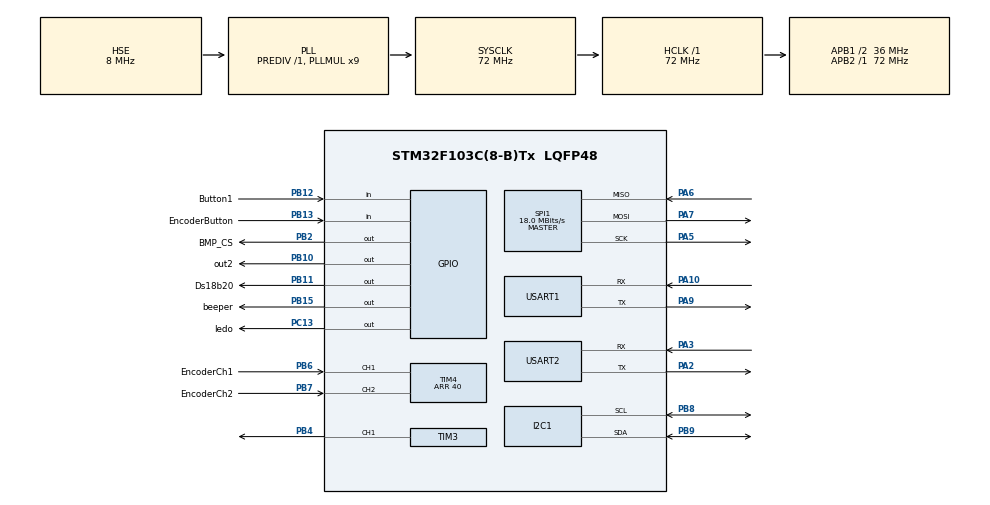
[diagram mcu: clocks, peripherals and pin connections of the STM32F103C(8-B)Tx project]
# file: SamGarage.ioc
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Dma.Request0=USART2_TX
Dma.USART2_TX.0.Direction=DMA_MEMORY_TO_PERIPH
Dma.USART2_TX.0.Instance=DMA1_Channel7
Dma.USART2_TX.0.MemDataAlignment=DMA_MDATAALIGN_BYTE
Dma.USART2_TX.0.MemInc=DMA_MINC_ENABLE
Dma.USART2_TX.0.Mode=DMA_NORMAL
Dma.USART2_TX.0.PeriphDataAlignment=DMA_PDATAALIGN_BYTE
Dma.USART2_TX.0.PeriphInc=DMA_PINC_DISABLE
Dma.USART2_TX.0.Priority=DMA_PRIORITY_LOW
I2C1.I2C_Mode=I2C_Fast
Mcu.Family=STM32F1
Mcu.Name=STM32F103C(8-B)Tx
Mcu.Package=LQFP48
NVIC.DMA1_Channel7_IRQn=true\:0\:0\:false\:false\:true\:false\:true\:true
NVIC.PriorityGroup=NVIC_PRIORITYGROUP_4
NVIC.RTC_IRQn=true\:0\:0\:false\:false\:true\:true\:true\:true
NVIC.TIM4_IRQn=true\:0\:0\:false\:false\:true\:true\:true\:true
NVIC.USART1_IRQn=true\:0\:0\:false\:false\:true\:true\:true\:true
NVIC.USART2_IRQn=true\:0\:0\:false\:false\:true\:true\:true\:true
PA10.Mode=Asynchronous
PA10.Signal=USART1_RX
PA13.Mode=Serial_Wire
PA13.Signal=SYS_JTMS-SWDIO
PA14.Mode=Serial_Wire
PA14.Signal=SYS_JTCK-SWCLK
PA2.Mode=Asynchronous
PA2.Signal=USART2_TX
PA3.Mode=Asynchronous
PA3.Signal=USART2_RX
PA5.Mode=Full_Duplex_Master
PA5.Signal=SPI1_SCK
PA6.Mode=Full_Duplex_Master
PA6.Signal=SPI1_MISO
PA7.Mode=Full_Duplex_Master
PA7.Signal=SPI1_MOSI
PA9.Mode=Asynchronous
PA9.Signal=USART1_TX
PB10.GPIO_Label=out2
PB10.GPIO_Speed=GPIO_SPEED_FREQ_HIGH
PB10.Signal=GPIO_Output
PB11.GPIO_Label=Ds18b20
PB11.GPIO_ModeDefaultOutputPP=GPIO_MODE_OUTPUT_OD
PB11.GPIO_PuPd=GPIO_NOPULL
PB11.GPIO_Speed=GPIO_SPEED_FREQ_HIGH
PB11.PinState=GPIO_PIN_SET
PB11.Signal=GPIO_Output
PB12.GPIO_Label=Button1
PB12.GPIO_PuPd=GPIO_PULLUP
PB12.Signal=GPIO_Input
PB13.GPIO_Label=EncoderButton
PB13.Signal=GPIO_Input
PB15.GPIO_Label=beeper
PB15.GPIO_PuPd=GPIO_PULLUP
PB15.GPIO_Speed=GPIO_SPEED_FREQ_HIGH
PB15.PinState=GPIO_PIN_SET
PB15.Signal=GPIO_Output
PB2.GPIO_Label=BMP_CS
PB2.Signal=GPIO_Output
PB4.Signal=S_TIM3_CH1
PB6.GPIO_Label=EncoderCh1
PB6.Signal=S_TIM4_CH1
PB7.GPIO_Label=EncoderCh2
PB7.Signal=S_TIM4_CH2
PB8.Mode=I2C
PB8.Signal=I2C1_SCL
PB9.Mode=I2C
PB9.Signal=I2C1_SDA
PC13-TAMPER-RTC.GPIO_Label=ledo
PC13-TAMPER-RTC.PinState=GPIO_PIN_SET
PC13-TAMPER-RTC.Signal=GPIO_Output
PC14-OSC32_IN.Mode=LSE-External-Oscillator
PC14-OSC32_IN.Signal=RCC_OSC32_IN
PC15-OSC32_OUT.Mode=LSE-External-Oscillator
PC15-OSC32_OUT.Signal=RCC_OSC32_OUT
PD0-OSC_IN.Mode=HSE-External-Oscillator
PD0-OSC_IN.Signal=RCC_OSC_IN
PD1-OSC_OUT.Mode=HSE-External-Oscillator
PD1-OSC_OUT.Signal=RCC_OSC_OUT
ProjectManager.HeapSize=0x200
ProjectManager.StackSize=0x400
ProjectManager.TargetToolchain=STM32CubeIDE
RCC.AHBFreq_Value=72000000
RCC.APB1CLKDivider=RCC_HCLK_DIV2
RCC.APB1Freq_Value=36000000
RCC.APB1TimFreq_Value=72000000
RCC.APB2Freq_Value=72000000
RCC.APB2TimFreq_Value=72000000
RCC.HCLKFreq_Value=72000000
RCC.PLLMUL=RCC_PLL_MUL9
RCC.PLLSourceVirtual=RCC_PLLSOURCE_HSE
RCC.SYSCLKFreq_VALUE=72000000
RCC.SYSCLKSource=RCC_SYSCLKSOURCE_PLLCLK
RCC.USBFreq_Value=48000000
RCC.USBPrescaler=RCC_USBCLKSOURCE_PLL_DIV1_5
RTC.AsynchPrediv=RTC_AUTO_1_SECOND
RTC.AutoPrediv=RTC_AUTO_1_SECOND
RTC.Format=RTC_FORMAT_BIN
SH.S_TIM3_CH1.0=TIM3_CH1,PWM Generation1 CH1
SH.S_TIM4_CH1.0=TIM4_CH1,Encoder_Interface
SH.S_TIM4_CH2.0=TIM4_CH2,Encoder_Interface
SPI1.BaudRatePrescaler=SPI_BAUDRATEPRESCALER_4
SPI1.CalculateBaudRate=18.0 MBits/s
SPI1.Direction=SPI_DIRECTION_2LINES
SPI1.Mode=SPI_MODE_MASTER
SPI1.VirtualType=VM_MASTER
TIM2.AutoReloadPreload=TIM_AUTORELOAD_PRELOAD_DISABLE
TIM2.Period=65000
TIM2.Prescaler=71
TIM3.Channel-PWM\ Generation1\ CH1=TIM_CHANNEL_1
TIM3.Period=5000
TIM3.Prescaler=14400
TIM4.IC1Filter=15
TIM4.IC2Filter=15
TIM4.Period=40
USART1.VirtualMode=VM_ASYNC
USART2.VirtualMode=VM_ASYNC
VP_RTC_No_RTC_Output.Mode=RTC_OUT_NO
VP_RTC_VS_RTC_Activate.Mode=RTC_Enabled
VP_TIM2_VS_ClockSourceINT.Mode=Internal
VP_TIM3_VS_ClockSourceINT.Mode=Internal
board=custom

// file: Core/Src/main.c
/* USER CODE BEGIN Header */
/**
  ******************************************************************************
  * @file           : main.c
  * @brief          : Main program body
  ******************************************************************************
  * @attention
  *
  * Copyright (c) 2022 STMicroelectronics.
  * All rights reserved.
  *
  * This software is licensed under terms that can be found in the LICENSE file
  * in the root directory of this software component.
  * If no LICENSE file comes with this software, it is provided AS-IS.
  *
  ******************************************************************************
  */
/* USER CODE END Header */
#include "main.h"

/* USER CODE BEGIN Includes */
#include "usart_ring.h"

#include "ssd1306.h"
//#include "string.h"
/* USER CODE END Includes */

 I2C_HandleTypeDef hi2c1;

RTC_HandleTypeDef hrtc;

SPI_HandleTypeDef hspi1;

TIM_HandleTypeDef htim2;
TIM_HandleTypeDef htim3;
TIM_HandleTypeDef htim4;

UART_HandleTypeDef huart1;
UART_HandleTypeDef huart2;
DMA_HandleTypeDef hdma_usart2_tx;

void SystemClock_Config(void);
static void MX_GPIO_Init(void);
static void MX_I2C1_Init(void);
static void MX_TIM4_Init(void);
static void MX_USART1_UART_Init(void);
static void MX_SPI1_Init(void);
static void MX_RTC_Init(void);
static void MX_DMA_Init(void);
static void MX_TIM2_Init(void);
static void MX_USART2_UART_Init(void);
static void MX_TIM3_Init(void);

int main(void)
{

  /* MCU Configuration--------------------------------------------------------*/

  /* Reset of all peripherals, Initializes the Flash interface and the Systick. */
  HAL_Init();

  /* USER CODE BEGIN Init */
//  HAL_Delay(800);
  /* USER CODE END Init */

  /* Configure the system clock */
  SystemClock_Config();

  /* Initialize all configured peripherals */
  MX_GPIO_Init();
  MX_I2C1_Init();
  MX_TIM4_Init();
  MX_USART1_UART_Init();
  MX_SPI1_Init();
  MX_RTC_Init();
  MX_DMA_Init();
  MX_TIM2_Init();
  MX_USART2_UART_Init();
  MX_TIM3_Init();
  /* USER CODE BEGIN 2 */
  __HAL_UART_ENABLE_IT(&MYUART, UART_IT_RXNE); // включить прерывания usart'a
  #define SIZE_BF 32

  //HAL_GPIO_TogglePin(led_GPIO_Port,	led_Pin);
  HAL_TIM_Encoder_Start_IT(&htim4, TIM_CHANNEL_1);

  init();
  loop();
  /* USER CODE END 2 */

  /* Infinite loop */
  /* USER CODE BEGIN WHILE */
  while (1)
  {
/*	  if (uart_available())
	  {
		  unsigned char a = (char)uart_read();
	  	  HAL_UART_Transmit(&huart1, &a, 1, 20);
	  }

	  delay(100);*/
    /* USER CODE END WHILE */

  }
}

void SystemClock_Config(void)
{
  RCC_OscInitTypeDef RCC_OscInitStruct = {0};
  RCC_ClkInitTypeDef RCC_ClkInitStruct = {0};
  RCC_PeriphCLKInitTypeDef PeriphClkInit = {0};

  /** Initializes the RCC Oscillators according to the specified parameters
  * in the RCC_OscInitTypeDef structure.
  */
  RCC_OscInitStruct.OscillatorType = RCC_OSCILLATORTYPE_LSI|RCC_OSCILLATORTYPE_HSE;
  RCC_OscInitStruct.HSEState = RCC_HSE_ON;
  RCC_OscInitStruct.HSEPredivValue = RCC_HSE_PREDIV_DIV1;
  RCC_OscInitStruct.HSIState = RCC_HSI_ON;
  RCC_OscInitStruct.LSIState = RCC_LSI_ON;
  RCC_OscInitStruct.PLL.PLLState = RCC_PLL_ON;
  RCC_OscInitStruct.PLL.PLLSource = RCC_PLLSOURCE_HSE;
  RCC_OscInitStruct.PLL.PLLMUL = RCC_PLL_MUL9;
  if (HAL_RCC_OscConfig(&RCC_OscInitStruct) != HAL_OK)
  {
    Error_Handler();
  }

  /** Initializes the CPU, AHB and APB buses clocks
  */
  RCC_ClkInitStruct.ClockType = RCC_CLOCKTYPE_HCLK|RCC_CLOCKTYPE_SYSCLK
                              |RCC_CLOCKTYPE_PCLK1|RCC_CLOCKTYPE_PCLK2;
  RCC_ClkInitStruct.SYSCLKSource = RCC_SYSCLKSOURCE_PLLCLK;
  RCC_ClkInitStruct.AHBCLKDivider = RCC_SYSCLK_DIV1;
  RCC_ClkInitStruct.APB1CLKDivider = RCC_HCLK_DIV2;
  RCC_ClkInitStruct.APB2CLKDivider = RCC_HCLK_DIV1;

  if (HAL_RCC_ClockConfig(&RCC_ClkInitStruct, FLASH_LATENCY_2) != HAL_OK)
  {
    Error_Handler();
  }
  PeriphClkInit.PeriphClockSelection = RCC_PERIPHCLK_RTC;
  PeriphClkInit.RTCClockSelection = RCC_RTCCLKSOURCE_LSI;
  if (HAL_RCCEx_PeriphCLKConfig(&PeriphClkInit) != HAL_OK)
  {
    Error_Handler();
  }
}

static void MX_I2C1_Init(void)
{

  hi2c1.Instance = I2C1;
  hi2c1.Init.ClockSpeed = 400000;
  hi2c1.Init.DutyCycle = I2C_DUTYCYCLE_2;
  hi2c1.Init.OwnAddress1 = 0;
  hi2c1.Init.AddressingMode = I2C_ADDRESSINGMODE_7BIT;
  hi2c1.Init.DualAddressMode = I2C_DUALADDRESS_DISABLE;
  hi2c1.Init.OwnAddress2 = 0;
  hi2c1.Init.GeneralCallMode = I2C_GENERALCALL_DISABLE;
  hi2c1.Init.NoStretchMode = I2C_NOSTRETCH_DISABLE;
  if (HAL_I2C_Init(&hi2c1) != HAL_OK)
  {
    Error_Handler();
  }

}

static void MX_RTC_Init(void)
{

  RTC_TimeTypeDef sTime = {0};
  RTC_DateTypeDef DateToUpdate = {0};

  /** Initialize RTC Only
  */
  hrtc.Instance = RTC;
  hrtc.Init.AsynchPrediv = RTC_AUTO_1_SECOND;
  hrtc.Init.OutPut = RTC_OUTPUTSOURCE_NONE;
  if (HAL_RTC_Init(&hrtc) != HAL_OK)
  {
    Error_Handler();
  }

  /** Initialize RTC and set the Time and Date
  */
  sTime.Hours = 0;
  sTime.Minutes = 0;
  sTime.Seconds = 0;

  if (HAL_RTC_SetTime(&hrtc, &sTime, RTC_FORMAT_BIN) != HAL_OK)
  {
    Error_Handler();
  }
  DateToUpdate.WeekDay = RTC_WEEKDAY_MONDAY;
  DateToUpdate.Month = RTC_MONTH_JANUARY;
  DateToUpdate.Date = 1;
  DateToUpdate.Year = 0;

  if (HAL_RTC_SetDate(&hrtc, &DateToUpdate, RTC_FORMAT_BIN) != HAL_OK)
  {
    Error_Handler();
  }

}

static void MX_SPI1_Init(void)
{

  /* SPI1 parameter configuration*/
  hspi1.Instance = SPI1;
  hspi1.Init.Mode = SPI_MODE_MASTER;
  hspi1.Init.Direction = SPI_DIRECTION_2LINES;
  hspi1.Init.DataSize = SPI_DATASIZE_8BIT;
  hspi1.Init.CLKPolarity = SPI_POLARITY_LOW;
  hspi1.Init.CLKPhase = SPI_PHASE_1EDGE;
  hspi1.Init.NSS = SPI_NSS_SOFT;
  hspi1.Init.BaudRatePrescaler = SPI_BAUDRATEPRESCALER_4;
  hspi1.Init.FirstBit = SPI_FIRSTBIT_MSB;
  hspi1.Init.TIMode = SPI_TIMODE_DISABLE;
  hspi1.Init.CRCCalculation = SPI_CRCCALCULATION_DISABLE;
  hspi1.Init.CRCPolynomial = 10;
  if (HAL_SPI_Init(&hspi1) != HAL_OK)
  {
    Error_Handler();
  }

}

static void MX_TIM2_Init(void)
{

  TIM_ClockConfigTypeDef sClockSourceConfig = {0};
  TIM_MasterConfigTypeDef sMasterConfig = {0};

  htim2.Instance = TIM2;
  htim2.Init.Prescaler = 71;
  htim2.Init.CounterMode = TIM_COUNTERMODE_UP;
  htim2.Init.Period = 65000;
  htim2.Init.ClockDivision = TIM_CLOCKDIVISION_DIV1;
  htim2.Init.AutoReloadPreload = TIM_AUTORELOAD_PRELOAD_DISABLE;
  if (HAL_TIM_Base_Init(&htim2) != HAL_OK)
  {
    Error_Handler();
  }
  sClockSourceConfig.ClockSource = TIM_CLOCKSOURCE_INTERNAL;
  if (HAL_TIM_ConfigClockSource(&htim2, &sClockSourceConfig) != HAL_OK)
  {
    Error_Handler();
  }
  sMasterConfig.MasterOutputTrigger = TIM_TRGO_RESET;
  sMasterConfig.MasterSlaveMode = TIM_MASTERSLAVEMODE_DISABLE;
  if (HAL_TIMEx_MasterConfigSynchronization(&htim2, &sMasterConfig) != HAL_OK)
  {
    Error_Handler();
  }

}

static void MX_TIM3_Init(void)
{

  TIM_ClockConfigTypeDef sClockSourceConfig = {0};
  TIM_MasterConfigTypeDef sMasterConfig = {0};
  TIM_OC_InitTypeDef sConfigOC = {0};

  htim3.Instance = TIM3;
  htim3.Init.Prescaler = 14400;
  htim3.Init.CounterMode = TIM_COUNTERMODE_UP;
  htim3.Init.Period = 5000;
  htim3.Init.ClockDivision = TIM_CLOCKDIVISION_DIV1;
  htim3.Init.AutoReloadPreload = TIM_AUTORELOAD_PRELOAD_DISABLE;
  if (HAL_TIM_Base_Init(&htim3) != HAL_OK)
  {
    Error_Handler();
  }
  sClockSourceConfig.ClockSource = TIM_CLOCKSOURCE_INTERNAL;
  if (HAL_TIM_ConfigClockSource(&htim3, &sClockSourceConfig) != HAL_OK)
  {
    Error_Handler();
  }
  if (HAL_TIM_PWM_Init(&htim3) != HAL_OK)
  {
    Error_Handler();
  }
  sMasterConfig.MasterOutputTrigger = TIM_TRGO_RESET;
  sMasterConfig.MasterSlaveMode = TIM_MASTERSLAVEMODE_DISABLE;
  if (HAL_TIMEx_MasterConfigSynchronization(&htim3, &sMasterConfig) != HAL_OK)
  {
    Error_Handler();
  }
  sConfigOC.OCMode = TIM_OCMODE_PWM1;
  sConfigOC.Pulse = 0;
  sConfigOC.OCPolarity = TIM_OCPOLARITY_HIGH;
  sConfigOC.OCFastMode = TIM_OCFAST_DISABLE;
  if (HAL_TIM_PWM_ConfigChannel(&htim3, &sConfigOC, TIM_CHANNEL_1) != HAL_OK)
  {
    Error_Handler();
  }
  HAL_TIM_MspPostInit(&htim3);

}

static void MX_TIM4_Init(void)
{

  TIM_Encoder_InitTypeDef sConfig = {0};
  TIM_MasterConfigTypeDef sMasterConfig = {0};

  htim4.Instance = TIM4;
  htim4.Init.Prescaler = 0;
  htim4.Init.CounterMode = TIM_COUNTERMODE_UP;
  htim4.Init.Period = 40;
  htim4.Init.ClockDivision = TIM_CLOCKDIVISION_DIV1;
  htim4.Init.AutoReloadPreload = TIM_AUTORELOAD_PRELOAD_DISABLE;
  sConfig.EncoderMode = TIM_ENCODERMODE_TI1;
  sConfig.IC1Polarity = TIM_ICPOLARITY_RISING;
  sConfig.IC1Selection = TIM_ICSELECTION_DIRECTTI;
  sConfig.IC1Prescaler = TIM_ICPSC_DIV1;
  sConfig.IC1Filter = 15;
  sConfig.IC2Polarity = TIM_ICPOLARITY_RISING;
  sConfig.IC2Selection = TIM_ICSELECTION_DIRECTTI;
  sConfig.IC2Prescaler = TIM_ICPSC_DIV1;
  sConfig.IC2Filter = 15;
  if (HAL_TIM_Encoder_Init(&htim4, &sConfig) != HAL_OK)
  {
    Error_Handler();
  }
  sMasterConfig.MasterOutputTrigger = TIM_TRGO_RESET;
  sMasterConfig.MasterSlaveMode = TIM_MASTERSLAVEMODE_DISABLE;
  if (HAL_TIMEx_MasterConfigSynchronization(&htim4, &sMasterConfig) != HAL_OK)
  {
    Error_Handler();
  }

}

static void MX_USART1_UART_Init(void)
{

  huart1.Instance = USART1;
  huart1.Init.BaudRate = 115200;
  huart1.Init.WordLength = UART_WORDLENGTH_8B;
  huart1.Init.StopBits = UART_STOPBITS_1;
  huart1.Init.Parity = UART_PARITY_NONE;
  huart1.Init.Mode = UART_MODE_TX_RX;
  huart1.Init.HwFlowCtl = UART_HWCONTROL_NONE;
  huart1.Init.OverSampling = UART_OVERSAMPLING_16;
  if (HAL_UART_Init(&huart1) != HAL_OK)
  {
    Error_Handler();
  }

}

static void MX_USART2_UART_Init(void)
{

  huart2.Instance = USART2;
  huart2.Init.BaudRate = 115200;
  huart2.Init.WordLength = UART_WORDLENGTH_8B;
  huart2.Init.StopBits = UART_STOPBITS_1;
  huart2.Init.Parity = UART_PARITY_NONE;
  huart2.Init.Mode = UART_MODE_TX_RX;
  huart2.Init.HwFlowCtl = UART_HWCONTROL_NONE;
  huart2.Init.OverSampling = UART_OVERSAMPLING_16;
  if (HAL_UART_Init(&huart2) != HAL_OK)
  {
    Error_Handler();
  }

}

static void MX_DMA_Init(void)
{

  /* DMA controller clock enable */
  __HAL_RCC_DMA1_CLK_ENABLE();

  /* DMA interrupt init */
  /* DMA1_Channel7_IRQn interrupt configuration */
  HAL_NVIC_SetPriority(DMA1_Channel7_IRQn, 0, 0);
  HAL_NVIC_EnableIRQ(DMA1_Channel7_IRQn);

}

static void MX_GPIO_Init(void)
{
  GPIO_InitTypeDef GPIO_InitStruct = {0};

  /* GPIO Ports Clock Enable */
  __HAL_RCC_GPIOC_CLK_ENABLE();
  __HAL_RCC_GPIOD_CLK_ENABLE();
  __HAL_RCC_GPIOA_CLK_ENABLE();
  __HAL_RCC_GPIOB_CLK_ENABLE();

  /*Configure GPIO pin Output Level */
  HAL_GPIO_WritePin(ledo_GPIO_Port, ledo_Pin, GPIO_PIN_SET);

  /*Configure GPIO pin Output Level */
  HAL_GPIO_WritePin(GPIOB, BMP_CS_Pin|out2_Pin, GPIO_PIN_RESET);

  /*Configure GPIO pin Output Level */
  HAL_GPIO_WritePin(GPIOB, Ds18b20_Pin|beeper_Pin, GPIO_PIN_SET);

  /*Configure GPIO pin : ledo_Pin */
  GPIO_InitStruct.Pin = ledo_Pin;
  GPIO_InitStruct.Mode = GPIO_MODE_OUTPUT_PP;
  GPIO_InitStruct.Pull = GPIO_NOPULL;
  GPIO_InitStruct.Speed = GPIO_SPEED_FREQ_LOW;
  HAL_GPIO_Init(ledo_GPIO_Port, &GPIO_InitStruct);

  /*Configure GPIO pin : BMP_CS_Pin */
  GPIO_InitStruct.Pin = BMP_CS_Pin;
  GPIO_InitStruct.Mode = GPIO_MODE_OUTPUT_PP;
  GPIO_InitStruct.Pull = GPIO_NOPULL;
  GPIO_InitStruct.Speed = GPIO_SPEED_FREQ_LOW;
  HAL_GPIO_Init(BMP_CS_GPIO_Port, &GPIO_InitStruct);

  /*Configure GPIO pin : out2_Pin */
  GPIO_InitStruct.Pin = out2_Pin;
  GPIO_InitStruct.Mode = GPIO_MODE_OUTPUT_PP;
  GPIO_InitStruct.Pull = GPIO_NOPULL;
  GPIO_InitStruct.Speed = GPIO_SPEED_FREQ_HIGH;
  HAL_GPIO_Init(out2_GPIO_Port, &GPIO_InitStruct);

  /*Configure GPIO pin : Ds18b20_Pin */
  GPIO_InitStruct.Pin = Ds18b20_Pin;
  GPIO_InitStruct.Mode = GPIO_MODE_OUTPUT_OD;
  GPIO_InitStruct.Pull = GPIO_NOPULL;
  GPIO_InitStruct.Speed = GPIO_SPEED_FREQ_HIGH;
  HAL_GPIO_Init(Ds18b20_GPIO_Port, &GPIO_InitStruct);

  /*Configure GPIO pin : Button1_Pin */
  GPIO_InitStruct.Pin = Button1_Pin;
  GPIO_InitStruct.Mode = GPIO_MODE_INPUT;
  GPIO_InitStruct.Pull = GPIO_PULLUP;
  HAL_GPIO_Init(Button1_GPIO_Port, &GPIO_InitStruct);

  /*Configure GPIO pin : EncoderButton_Pin */
  GPIO_InitStruct.Pin = EncoderButton_Pin;
  GPIO_InitStruct.Mode = GPIO_MODE_INPUT;
  GPIO_InitStruct.Pull = GPIO_NOPULL;
  HAL_GPIO_Init(EncoderButton_GPIO_Port, &GPIO_InitStruct);

  /*Configure GPIO pin : beeper_Pin */
  GPIO_InitStruct.Pin = beeper_Pin;
  GPIO_InitStruct.Mode = GPIO_MODE_OUTPUT_PP;
  GPIO_InitStruct.Pull = GPIO_PULLUP;
  GPIO_InitStruct.Speed = GPIO_SPEED_FREQ_HIGH;
  HAL_GPIO_Init(beeper_GPIO_Port, &GPIO_InitStruct);

}

void Error_Handler(void)
{
  __disable_irq();
  while (1)
  {
  }
}
